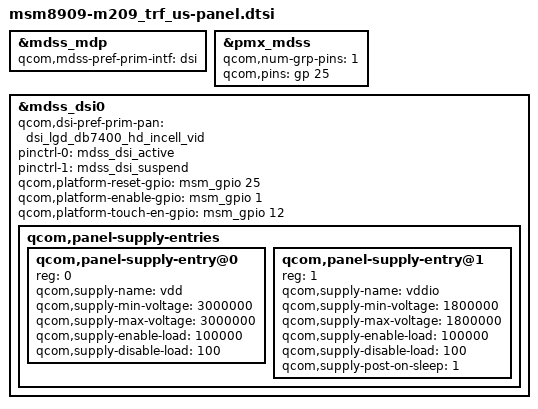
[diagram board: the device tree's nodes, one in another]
/* Copyright (c) 2013, Code Aurora Forum. All rights reserved.
 *
 * This program is free software; you can redistribute it and/or modify
 * it under the terms of the GNU General Public License version 2 and
 * only version 2 as published by the Free Software Foundation.
 *
 * This program is distributed in the hope that it will be useful,
 * but WITHOUT ANY WARRANTY; without even the implied warranty of
 * MERCHANTABILITY or FITNESS FOR A PARTICULAR PURPOSE.  See the
 * GNU General Public License for more details.
 */

#include "../msm8909-lge-common/dsi-panel-lgd-db7400-720p-video.dtsi"
#include "../msm8909-lge-common/msm8909-backlight-rt8542.dtsi"


&mdss_mdp {
		qcom,mdss-pref-prim-intf = "dsi";
};

&pmx_mdss {
		qcom,num-grp-pins = <1>;
		qcom,pins = <&gp 25>;
};
&mdss_dsi0 {
		qcom,dsi-pref-prim-pan = <&dsi_lgd_db7400_hd_incell_vid>;
		pinctrl-names = "mdss_default", "mdss_sleep";
		pinctrl-0 = <&mdss_dsi_active>;
		pinctrl-1 = <&mdss_dsi_suspend>;
		qcom,platform-reset-gpio = <&msm_gpio 25 0>;
		qcom,platform-enable-gpio = <&msm_gpio 1 0>;
		qcom,platform-touch-en-gpio = <&msm_gpio 12 0>;

		qcom,panel-supply-entries {
			#address-cells = <1>;
			#size-cells = <0>;

			qcom,panel-supply-entry@0 {
				reg = <0>;
				qcom,supply-name = "vdd";
				qcom,supply-min-voltage = <3000000>;
				qcom,supply-max-voltage = <3000000>;
				qcom,supply-enable-load = <100000>;
				qcom,supply-disable-load = <100>;
			};

			qcom,panel-supply-entry@1 {
				reg = <1>;
				qcom,supply-name = "vddio";
				qcom,supply-min-voltage = <1800000>;
				qcom,supply-max-voltage = <1800000>;
				qcom,supply-enable-load = <100000>;
				qcom,supply-disable-load = <100>;
				qcom,supply-post-on-sleep = <1>;
			};
		};
};
